# PIC32CX5109BZ31032 register map
Vendor: Microchip Technology; Series: PIC32CXBZ31; File version: 0
CPU: CM4 r0p1, little endian, MPU, FPU, 3 interrupt priority bits, 43 interrupts
Registers are 32-bit, read-write, reset 0x0 unless marked. A register's access mark holds for its fields unless they carry their own. Offsets are from the block's base; [hi:lo] are bit positions; {n}, {i} and the like mark numbered series; 'fields as' and 'values as' point back to an identical list.

## PCHE — this is the PCHE
Base 0x44012400
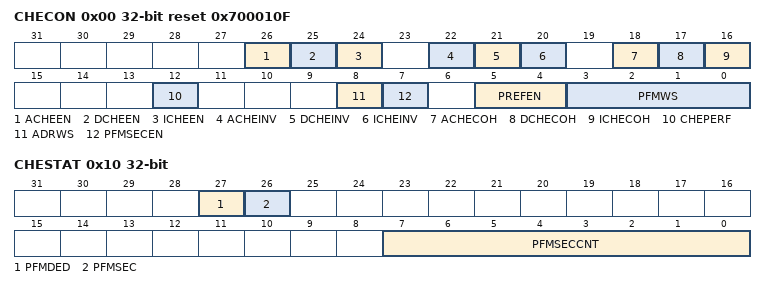
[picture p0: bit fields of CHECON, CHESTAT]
0x00 CHECON reset 0x700010F
  [26] ACHEEN, [25] DCHEEN, [24] ICHEEN, [22] ACHEINV, [21] DCHEINV, [20] ICHEINV, [18] ACHECOH, [17] DCHECOH, [16] ICHECOH, [12] CHEPERF, [8] ADRWS, [7] PFMSECEN, [5:4] PREFEN, [3:0] PFMWS
0x04 CHECONCLR
0x08 CHECONSET
0x0C CHECONINV
0x10 CHESTAT
  [27] PFMDED, [26] PFMSEC, [7:0] PFMSECCNT
0x14 CHESTATCLR
0x18 CHESTATSET
0x1C CHESTATINV
0x20 CHEHIT
0x24 CHEHITCLR
0x28 CHEHITSET
0x2C CHEHITINV
0x30 CHEMIS
0x34 CHEMISCLR
0x38 CHEMISSET
0x3C CHEMISINV

## PFW — flash wrapper
Base 0x44000800
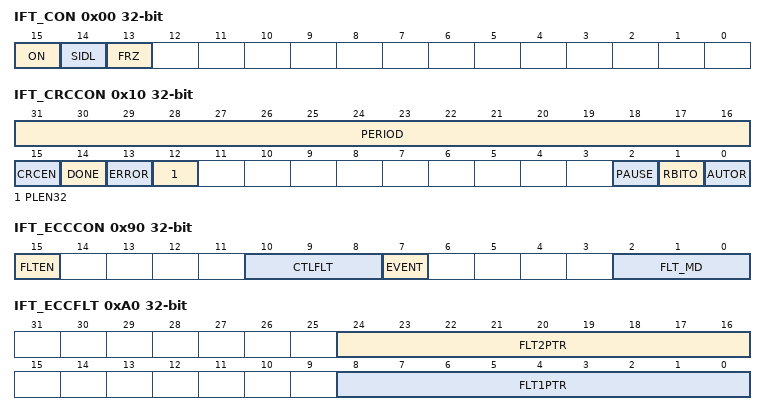
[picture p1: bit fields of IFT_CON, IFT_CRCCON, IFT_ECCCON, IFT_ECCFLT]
0x00 IFT_CON
  [15] ON, [14] SIDL, [13] FRZ
0x10 IFT_CRCCON
  [31:16] PERIOD, [15] CRCEN, [14] DONE, [13] ERROR, [12] PLEN32, [2] PAUSE, [1] RBITO, [0] AUTOR
0x20 IFT_CRCMADR
0x30 IFT_CRCMLEN
  [23:0] CRCMLEN
0x40 IFT_CRCIV
0x50 IFT_CRCACC
0x60 IFT_CRCPOLY
  [31:0] CYCPOLY
0x70 IFT_CRCFXOR
0x80 IFT_CRCSUM
0x90 IFT_ECCCON
  [15] FLTEN, [10:8] CTLFLT, [7] EVENT, [2:0] FLT_MD
0xA0 IFT_ECCFLT
  [24:16] FLT2PTR, [8:0] FLT1PTR
0xB0 IFT_ECCADR
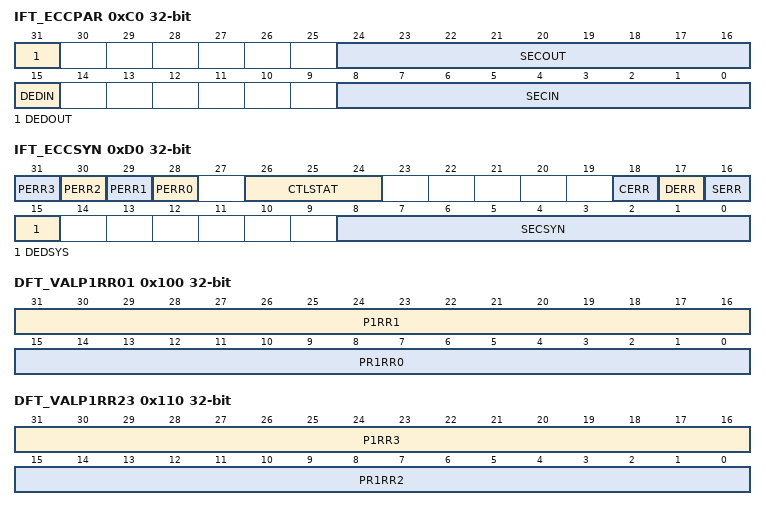
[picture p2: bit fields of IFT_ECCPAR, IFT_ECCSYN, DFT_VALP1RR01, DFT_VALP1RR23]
0xC0 IFT_ECCPAR
  [31] DEDOUT, [24:16] SECOUT, [15] DEDIN, [8:0] SECIN
0xD0 IFT_ECCSYN
  [n+28] PERR{n} (n=0..3), [26:24] CTLSTAT, [18] CERR, [17] DERR, [16] SERR, [15] DEDSYS, [8:0] SECSYN
0xF0 DFT_VALCON
  [15] VAL_ON
0x100 DFT_VALP1RR01
  [31:16] P1RR1, [15:0] PR1RR0
0x110 DFT_VALP1RR23
  [31:16] P1RR3, [15:0] PR1RR2
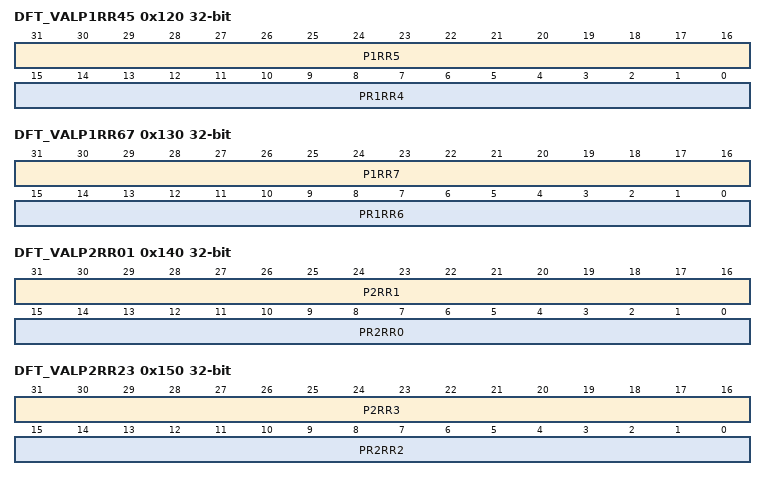
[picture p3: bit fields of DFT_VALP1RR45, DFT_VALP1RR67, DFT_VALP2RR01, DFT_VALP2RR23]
0x120 DFT_VALP1RR45
  [31:16] P1RR5, [15:0] PR1RR4
0x130 DFT_VALP1RR67
  [31:16] P1RR7, [15:0] PR1RR6
0x140 DFT_VALP2RR01
  [31:16] P2RR1, [15:0] PR2RR0
0x150 DFT_VALP2RR23
  [31:16] P2RR3, [15:0] PR2RR2
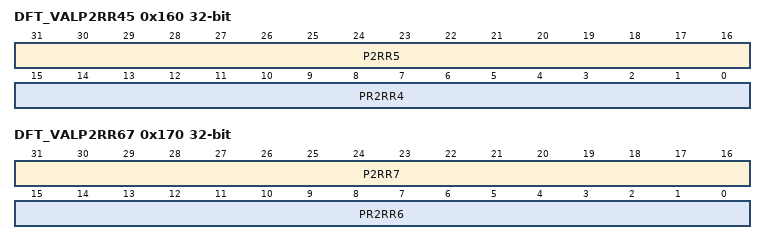
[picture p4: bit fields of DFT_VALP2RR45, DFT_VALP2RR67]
0x160 DFT_VALP2RR45
  [31:16] P2RR5, [15:0] PR2RR4
0x170 DFT_VALP2RR67
  [31:16] P2RR7, [15:0] PR2RR6

## PMU — PMU SPI controller
Base 0x44013E00
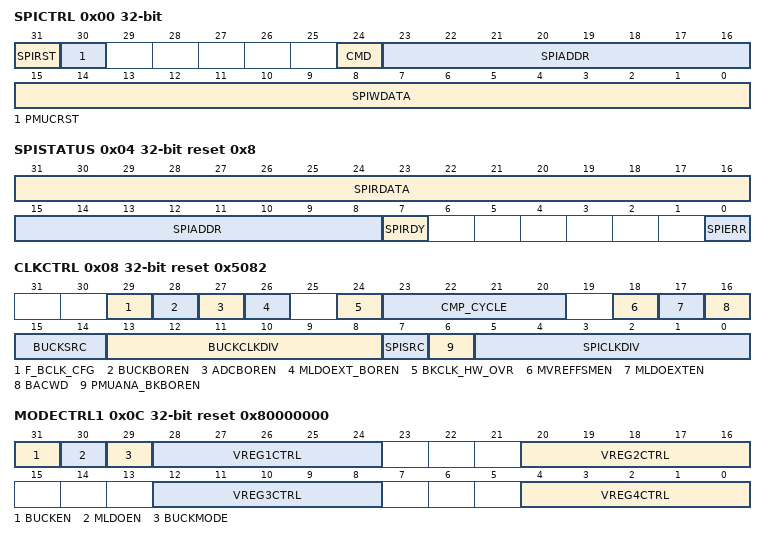
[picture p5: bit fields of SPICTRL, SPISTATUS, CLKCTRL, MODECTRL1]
0x00 SPICTRL
  [31] SPIRST, [30] PMUCRST, [24] CMD, [23:16] SPIADDR, [15:0] SPIWDATA
0x04 SPISTATUS reset 0x8
  [31:16] SPIRDATA, [15:8] SPIADDR, [7] SPIRDY, [0] SPIERR
0x08 CLKCTRL reset 0x5082
  [29] F_BCLK_CFG, [28] BUCKBOREN, [27] ADCBOREN, [26] MLDOEXT_BOREN, [24] BKCLK_HW_OVR, [23:20] CMP_CYCLE, [18] MVREFFSMEN, [17] MLDOEXTEN, [16] BACWD, [15:14] BUCKSRC, [13:8] BUCKCLKDIV, [7] SPISRC, [6] PMUANA_BKBOREN, [5:0] SPICLKDIV
0x0C MODECTRL1 reset 0x80000000
  [31] BUCKEN, [30] MLDOEN, [29] BUCKMODE, [36-8n:32-8n] VREG{n}CTRL (n=1..4)
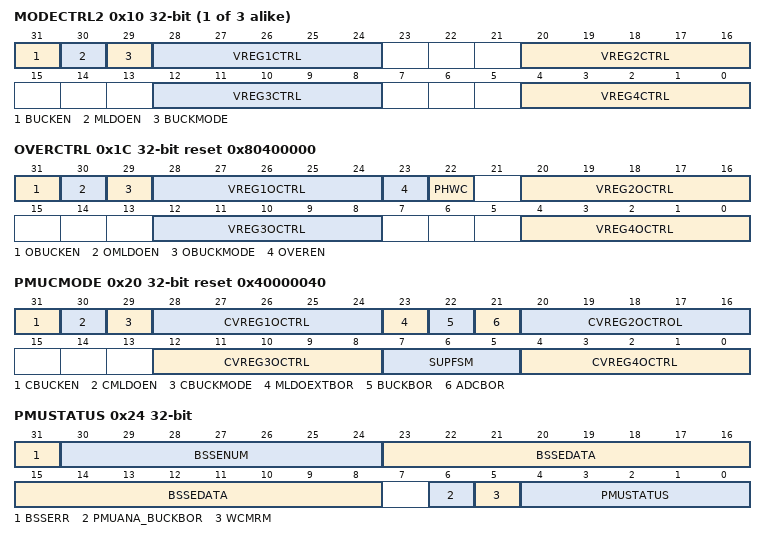
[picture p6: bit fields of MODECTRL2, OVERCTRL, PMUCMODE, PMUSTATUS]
{0x8+4i} MODECTRL{i} (i=2..4)
  fields as MODECTRL1
0x1C OVERCTRL reset 0x80400000
  [31] OBUCKEN, [30] OMLDOEN, [29] OBUCKMODE, [36-8n:32-8n] VREG{n}OCTRL (n=1..4), [23] OVEREN, [22] PHWC
0x20 PMUCMODE reset 0x40000040
  [31] CBUCKEN, [30] CMLDOEN, [29] CBUCKMODE, [28:24] CVREG1OCTRL, [23] MLDOEXTBOR, [22] BUCKBOR, [21] ADCBOR, [20:16] CVREG2OCTROL, [12:8] CVREG3OCTRL, [7:5] SUPFSM, [4:0] CVREG4OCTRL
0x24 PMUSTATUS
  [31] BSSERR, [30:24] BSSENUM, [23:8] BSSEDATA, [6] PMUANA_BUCKBOR, [5] WCMRM, [4:0] PMUSTATUS
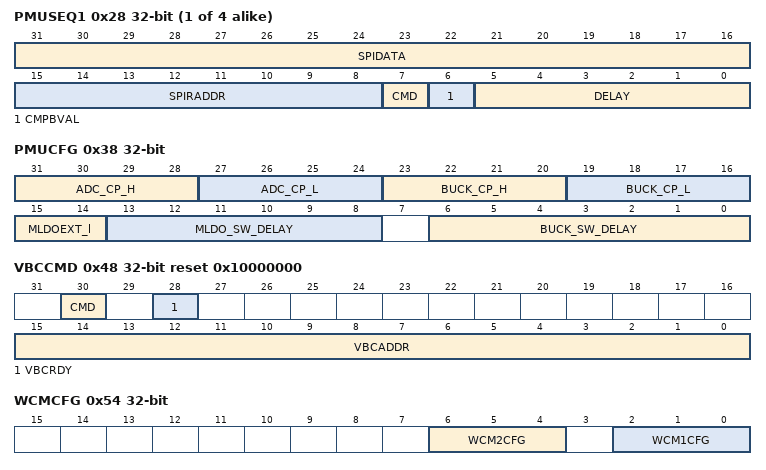
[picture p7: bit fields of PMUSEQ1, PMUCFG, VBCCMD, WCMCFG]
{0x24+4i} PMUSEQ{i} (i=1..4)
  [31:16] SPIDATA, [15:8] SPIRADDR, [7] CMD, [6] CMPBVAL, [5:0] DELAY
0x38 PMUCFG
  [31:28] ADC_CP_H, [27:24] ADC_CP_L, [23:20] BUCK_CP_H, [19:16] BUCK_CP_L, [15:14] MLDOEXT_l, [13:8] MLDO_SW_DELAY, [6:0] BUCK_SW_DELAY
0x48 VBCCMD reset 0x10000000
  [30] CMD, [28] VBCRDY, [15:0] VBCADDR
0x4C VBCWDATA
0x50 VBCRDATA
0x54 WCMCFG
  [6:4] WCM2CFG, [2:0] WCM1CFG
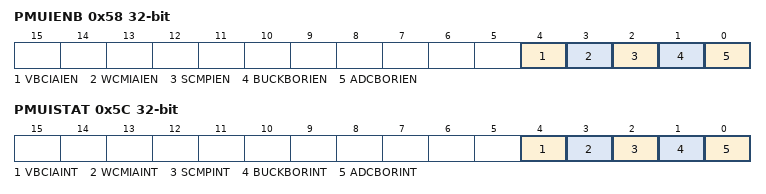
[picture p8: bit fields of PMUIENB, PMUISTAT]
0x58 PMUIENB
  [4] VBCIAIEN, [3] WCMIAIEN, [2] SCMPIEN, [1] BUCKBORIEN, [0] ADCBORIEN
0x5C PMUISTAT
  [4] VBCIAINT, [3] WCMIAINT, [2] SCMPINT, [1] BUCKBORINT, [0] ADCBORINT
0x60 WCMSIZ
  [9:8] SRAM1_SIZ
    0=NO_SRAM_RETENTION (FlexRAM is completely powered OFF); 1=16K_SRAM (16K Flex RAM available in retention); 2=32K_SRAM (32K Flex RAM available in retention)

## RAMECC
Base 0x41008000
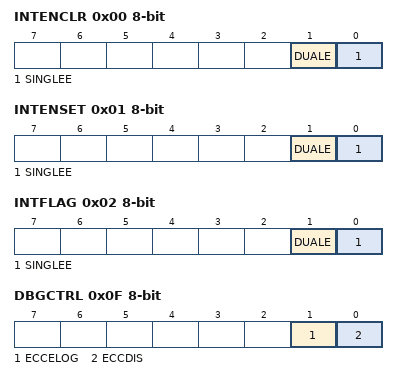
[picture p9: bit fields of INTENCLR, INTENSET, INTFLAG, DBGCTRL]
0x00 INTENCLR 8-bit — Interrupt Enable Clear
  [1] DUALE — Dual Bit ECC Error Interrupt Enable Clear
  [0] SINGLEE — Single Bit ECC Error Interrupt Enable Clear
0x01 INTENSET 8-bit — Interrupt Enable Set
  [1] DUALE — Dual Bit ECC Error Interrupt Enable Set
  [0] SINGLEE — Single Bit ECC Error Interrupt Enable Set
0x02 INTFLAG 8-bit — Interrupt Flag
  [1] DUALE — Dual Bit ECC Error Interrupt
  [0] SINGLEE — Single Bit ECC Error Interrupt
0x03 STATUS 8-bit ro
  [0] ECCDIS — ECC Disable
0x04 ERRADDR ro — Error Address
  [17:0] ERRADDR
0x0F DBGCTRL 8-bit — Debug Control
  [1] ECCELOG — ECC Error Log
  [0] ECCDIS — ECC Disable

## Notices in the file
Copyright (c) 2023 Microchip Technology Inc.
SPDX-License-Identifier: Apache-2.0
Licensed under the Apache License, Version 2.0 (the "License");
you may not use this file except in compliance with the License.
You may obtain a copy of the License at
http://www.apache.org/licenses/LICENSE-2.0
Unless required by applicable law or agreed to in writing, software
distributed under the License is distributed on an "AS IS" BASIS,
WITHOUT WARRANTIES OR CONDITIONS OF ANY KIND, either express or implied.
See the License for the specific language governing permissions and
limitations under the License.
